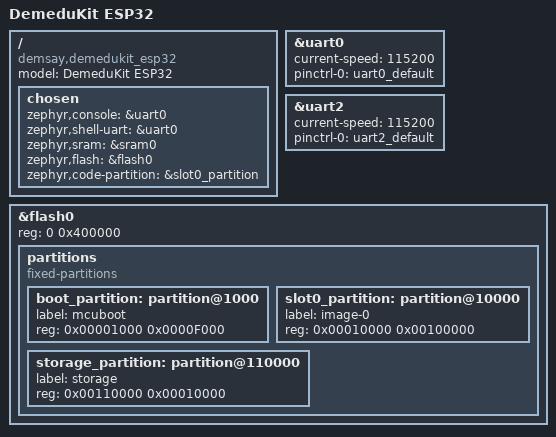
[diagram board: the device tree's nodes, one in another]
#include <xtensa/espressif/esp32/esp32_common.dtsi>
#include "demedukit_esp32-pinctrl.dtsi"

/ {
model = "DemeduKit ESP32";
compatible = "demsay,demedukit_esp32";

chosen {
zephyr,console = &uart0;
zephyr,shell-uart = &uart0;
zephyr,sram = &sram0;
zephyr,flash = &flash0;
zephyr,code-partition = &slot0_partition;
};
};

&uart0 {
status = "okay";
current-speed = <115200>;
pinctrl-0 = <&uart0_default>;
pinctrl-names = "default";
};

&uart2 {
status = "okay";
current-speed = <115200>;
pinctrl-0 = <&uart2_default>;
pinctrl-names = "default";
};

&flash0 {
status = "okay";
reg = <0 0x400000>;
partitions {
compatible = "fixed-partitions";
#address-cells = <1>;
#size-cells = <1>;
boot_partition: partition@1000 {
label = "mcuboot";
reg = <0x00001000 0x0000F000>;
};
slot0_partition: partition@10000 {
label = "image-0";
reg = <0x00010000 0x00100000>;
};
storage_partition: partition@110000 {
label = "storage";
reg = <0x00110000 0x00010000>;
};
};
};
